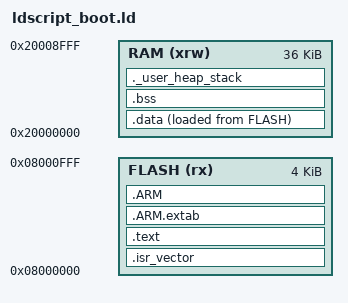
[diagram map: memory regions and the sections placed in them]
/* LGS R5.0 bootloader linker script — 4KB slot at the start of flash.
 * The application lives at 0x08001000 (see include/flash_layout.h). */

ENTRY(Reset_Handler)

_estack = ORIGIN(RAM) + LENGTH(RAM);

MEMORY
{
  FLASH (rx)  : ORIGIN = 0x08000000, LENGTH = 4K
  RAM   (xrw) : ORIGIN = 0x20000000, LENGTH = 36K
}

SECTIONS
{
  .isr_vector :
  {
    . = ALIGN(4);
    KEEP(*(.isr_vector))
    . = ALIGN(4);
  } >FLASH

  .text :
  {
    . = ALIGN(4);
    *(.text*)
    *(.rodata*)
    KEEP(*(.init))
    KEEP(*(.fini))
    . = ALIGN(4);
    _etext = .;
  } >FLASH

  .ARM.extab : { *(.ARM.extab*) } >FLASH
  .ARM       : { *(.ARM.exidx*) } >FLASH

  _sidata = LOADADDR(.data);

  .data :
  {
    . = ALIGN(4);
    _sdata = .;
    *(.data*)
    . = ALIGN(4);
    _edata = .;
  } >RAM AT> FLASH

  .bss :
  {
    . = ALIGN(4);
    _sbss = .;
    __bss_start__ = _sbss;
    *(.bss*)
    *(COMMON)
    . = ALIGN(4);
    _ebss = .;
    __bss_end__ = _ebss;
  } >RAM

  ._user_heap_stack :
  {
    . = ALIGN(8);
    PROVIDE(end = .);
    PROVIDE(_end = .);
    . = . + 0x100;
    . = ALIGN(8);
  } >RAM

  .ARM.attributes 0 : { *(.ARM.attributes) }
}
